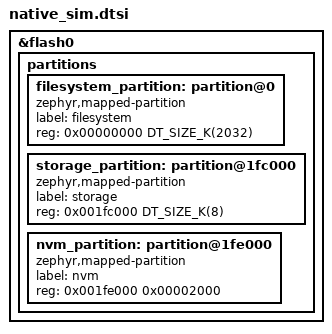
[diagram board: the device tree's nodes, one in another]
/* native_sim layout (host simulation, no mcuboot): applied to the application
 * image only. There is no real flash -- upstream's flash0 is a simulated
 * device -- so this replaces the upstream mcuboot-style layout with one for
 * the CircuitPython port: the whole simulated flash minus storage/nvm is the
 * user filesystem.
 */
&flash0 {
	/delete-node/ partitions;

	partitions {
		#address-cells = <1>;
		#size-cells = <1>;

		filesystem_partition: partition@0 {
			compatible = "zephyr,mapped-partition";
			label = "filesystem";
			reg = <0x00000000 DT_SIZE_K(2032)>;
		};

		storage_partition: partition@1fc000 {
			compatible = "zephyr,mapped-partition";
			label = "storage";
			reg = <0x001fc000 DT_SIZE_K(8)>;
		};

		nvm_partition: partition@1fe000 {
			compatible = "zephyr,mapped-partition";
			label = "nvm";
			reg = <0x001fe000 0x00002000>;
		};
	};
};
